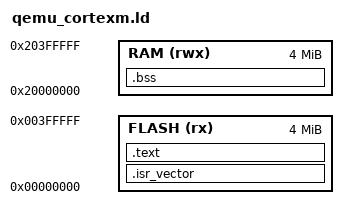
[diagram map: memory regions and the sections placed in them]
MEMORY
{
    FLASH (rx)  : ORIGIN = 0x00000000, LENGTH = 4M
    RAM   (rwx) : ORIGIN = 0x20000000, LENGTH = 4M
}

_estack = ORIGIN(RAM) + LENGTH(RAM);

SECTIONS
{
    .isr_vector :
    {
        KEEP(*(.isr_vector))
    } > FLASH

    .text :
    {
        *(.text*)
        *(.rodata*)
    } > FLASH

    .bss (NOLOAD) :
    {
        __bss_start__ = .;
        *(.bss*)
        *(COMMON)
        __bss_end__ = .;
    } > RAM
}
